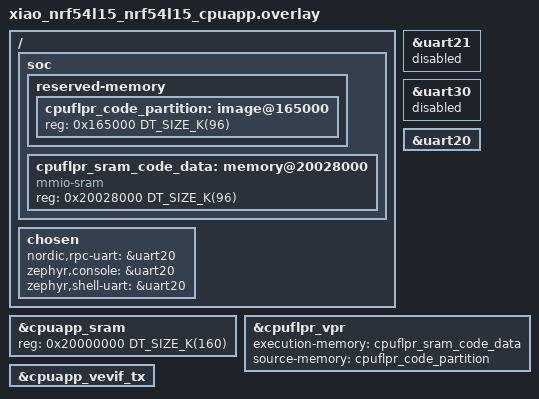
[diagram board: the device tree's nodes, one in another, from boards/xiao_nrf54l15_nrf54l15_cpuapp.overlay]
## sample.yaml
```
sample:
  description: nRF Connect SDK Intermediate Course by Nordic Developer Academy (https://academy.nordicsemi.com/)
  name: nRF Connect SDK Intermediate Course - Lesson 8 Exercise 2 Solution

common: 
    sysbuild: true
    build_only: true
    integration_platforms: 
        - xiao_nrf54l15/nrf54l15/cpuapp
        - nrf54l15dk/nrf54l15/cpuapp
    platform_exclude:
      - native_sim
    
```

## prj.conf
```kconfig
# GPIO for LED
CONFIG_GPIO=y

# UART Console
CONFIG_SERIAL=y
CONFIG_UART_CONSOLE=y
CONFIG_CONSOLE=y

# IPC Service for FLPR console forwarding
CONFIG_IPC_SERVICE=y
CONFIG_MBOX=y
CONFIG_HEAP_MEM_POOL_SIZE=8192
```

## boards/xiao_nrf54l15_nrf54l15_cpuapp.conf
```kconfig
CONFIG_PRINTK=y
CONFIG_SERIAL=y
CONFIG_LOG=y
CONFIG_GPIO=y
CONFIG_UART_CONSOLE=y
CONFIG_CONSOLE=y
CONFIG_LOG_PRINTK=y
CONFIG_LOG_BACKEND_UART=y
```

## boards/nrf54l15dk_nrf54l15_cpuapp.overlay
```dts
/ {
	soc {
		reserved-memory {
			#address-cells = <1>;
			#size-cells = <1>;
			cpuflpr_code_partition: image@165000 {
				/* FLPR core code partition */
				reg = <0x165000 DT_SIZE_K(96)>;
			};
		};

		cpuflpr_sram_code_data: memory@20028000 {
			compatible = "mmio-sram";
			reg = <0x20028000 DT_SIZE_K(96)>;
			#address-cells = <1>;
			#size-cells = <1>;
			ranges = <0x0 0x20028000 0x18000>;
		};
	};
};

&uart30 {
	status = "reserved";
};

&cpuapp_sram {
	reg = <0x20000000 DT_SIZE_K(160)>;
	ranges = <0x0 0x20000000 0x28000>;
};

&cpuflpr_vpr {
	status = "okay";
	execution-memory = <&cpuflpr_sram_code_data>;
	source-memory = <&cpuflpr_code_partition>;
};

&cpuapp_vevif_tx {
	status = "okay";
};
```

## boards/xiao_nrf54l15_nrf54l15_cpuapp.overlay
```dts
//this overlay is used in place of the snippets.

/ {
	soc {
		reserved-memory {
			#address-cells = <1>;
			#size-cells = <1>;
			cpuflpr_code_partition: image@165000 {
				/* FLPR core code partition */
				reg = <0x165000 DT_SIZE_K(96)>;
			};
		};

		cpuflpr_sram_code_data: memory@20028000 {
			compatible = "mmio-sram";
			reg = <0x20028000 DT_SIZE_K(96)>;
			#address-cells = <1>;
			#size-cells = <1>;
			ranges = <0x0 0x20028000 0x18000>;
		};
	};

	chosen {
		nordic,rpc-uart = &uart20;
		zephyr,console = &uart20;
		zephyr,shell-uart = &uart20;
	};
};

&uart21 {
	status = "reserved";
};

&uart30 {
    status = "disabled";  // Disable the old one
};

&uart20 {
	status = "okay";
};


&cpuapp_sram {
	reg = <0x20000000 DT_SIZE_K(160)>;
	ranges = <0x0 0x20000000 0x28000>;
};

&cpuflpr_vpr {
	status = "okay";
	execution-memory = <&cpuflpr_sram_code_data>;
	source-memory = <&cpuflpr_code_partition>;
};

&cpuapp_vevif_tx {
	status = "okay";
};
```

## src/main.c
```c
/*
 * Copyright (c) 2025 Nordic Semiconductor ASA
 *
 * SPDX-License-Identifier: LicenseRef-Nordic-5-Clause
 */

#include <zephyr/kernel.h>
#include <zephyr/drivers/gpio.h>
#include <zephyr/drivers/uart.h>
#include <zephyr/drivers/console/console.h>
#include <zephyr/mgmt/mcumgr/transport/serial.h>
#include <zephyr/ipc/ipc_service.h>

#define LED0_NODE DT_ALIAS(led0)
static const struct gpio_dt_spec led = GPIO_DT_SPEC_GET(LED0_NODE, gpios);

int main()
{
	int ret;
	bool led_is_on = true;

	if (!gpio_is_ready_dt(&led)) {
		printk("Error: device not ready\n");
		return -1;
	}

	ret = gpio_pin_configure_dt(&led, GPIO_OUTPUT_ACTIVE);
	if (ret < 0) {
		printk("Error: LED configuration failed\n");
		return ret;
	}
	printk("This application is running on the Application Core (CPUAPP)\n");
	printk("Hello from DevAcademy Intermediate, Lesson 8, Exercise 2\n");
	while (1) {

		led_is_on = !led_is_on;
		gpio_pin_toggle_dt(&led);
		printk("LED status: %s\n", led_is_on ? "ON" : "OFF");

		k_sleep(K_MSEC(5000));
	}

	return 0;
}
```
